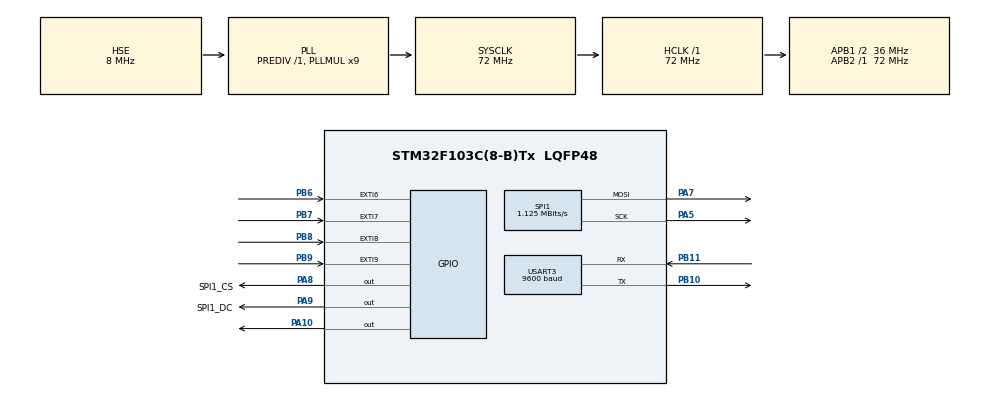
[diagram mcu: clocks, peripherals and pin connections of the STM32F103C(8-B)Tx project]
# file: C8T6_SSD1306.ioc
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Mcu.Family=STM32F1
Mcu.Name=STM32F103C(8-B)Tx
Mcu.Package=LQFP48
NVIC.EXTI9_5_IRQn=true\:0\:0\:false\:false\:true\:true
NVIC.PriorityGroup=NVIC_PRIORITYGROUP_4
NVIC.TIM2_IRQn=true\:0\:0\:false\:false\:true\:true
NVIC.USART3_IRQn=true\:0\:0\:false\:false\:true\:true
PA10.Signal=GPIO_Output
PA5.Mode=TX_Only_Simplex_Unidirect_Master
PA5.Signal=SPI1_SCK
PA7.Mode=TX_Only_Simplex_Unidirect_Master
PA7.Signal=SPI1_MOSI
PA8.GPIO_Label=SPI1_CS
PA8.GPIO_Speed=GPIO_SPEED_FREQ_LOW
PA8.PinState=GPIO_PIN_RESET
PA8.Signal=GPIO_Output
PA9.GPIO_Label=SPI1_DC
PA9.GPIO_Speed=GPIO_SPEED_FREQ_LOW
PA9.PinState=GPIO_PIN_RESET
PA9.Signal=GPIO_Output
PB10.Mode=Asynchronous
PB10.Signal=USART3_TX
PB11.Mode=Asynchronous
PB11.Signal=USART3_RX
PB6.Signal=GPXTI6
PB7.Signal=GPXTI7
PB8.Signal=GPXTI8
PB9.Signal=GPXTI9
PD0-OSC_IN.Mode=HSE-External-Oscillator
PD0-OSC_IN.Signal=RCC_OSC_IN
PD1-OSC_OUT.Mode=HSE-External-Oscillator
PD1-OSC_OUT.Signal=RCC_OSC_OUT
ProjectManager.HeapSize=0x200
ProjectManager.StackSize=0x400
ProjectManager.TargetToolchain=TrueSTUDIO
RCC.ADCPresc=RCC_ADCPCLK2_DIV6
RCC.AHBFreq_Value=72000000
RCC.APB1CLKDivider=RCC_HCLK_DIV2
RCC.APB1Freq_Value=36000000
RCC.APB1TimFreq_Value=72000000
RCC.APB2Freq_Value=72000000
RCC.APB2TimFreq_Value=72000000
RCC.HCLKFreq_Value=72000000
RCC.PLLMUL=RCC_PLL_MUL9
RCC.PLLSourceVirtual=RCC_PLLSOURCE_HSE
RCC.SYSCLKFreq_VALUE=72000000
RCC.SYSCLKSource=RCC_SYSCLKSOURCE_PLLCLK
RCC.USBFreq_Value=72000000
SPI1.BaudRatePrescaler=SPI_BAUDRATEPRESCALER_64
SPI1.CalculateBaudRate=1.125 MBits/s
SPI1.Direction=SPI_DIRECTION_2LINES
SPI1.Mode=SPI_MODE_MASTER
SPI1.VirtualType=VM_MASTER
TIM2.Period=9999
TIM2.Prescaler=7199
USART3.BaudRate=9600
USART3.VirtualMode=VM_ASYNC
VP_SYS_VS_ND.Mode=No_Debug
VP_TIM2_VS_ClockSourceINT.Mode=Internal
board=C8T6_SSD1306

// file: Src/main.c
/**
  ******************************************************************************
  * File Name          : main.c
  * Description        : Main program body
  ******************************************************************************
  ** This notice applies to any and all portions of this file
  * that are not between comment pairs USER CODE BEGIN and
  * USER CODE END. Other portions of this file, whether
  * inserted by the user or by software development tools
  * are owned by their respective copyright owners.
  *
  * COPYRIGHT(c) 2017 STMicroelectronics
  *
  * Redistribution and use in source and binary forms, with or without modification,
  * are permitted provided that the following conditions are met:
  *   1. Redistributions of source code must retain the above copyright notice,
  *      this list of conditions and the following disclaimer.
  *   2. Redistributions in binary form must reproduce the above copyright notice,
  *      this list of conditions and the following disclaimer in the documentation
  *      and/or other materials provided with the distribution.
  *   3. Neither the name of STMicroelectronics nor the names of its contributors
  *      may be used to endorse or promote products derived from this software
  *      without specific prior written permission.
  *
  * THIS SOFTWARE IS PROVIDED BY THE COPYRIGHT HOLDERS AND CONTRIBUTORS "AS IS"
  * AND ANY EXPRESS OR IMPLIED WARRANTIES, INCLUDING, BUT NOT LIMITED TO, THE
  * IMPLIED WARRANTIES OF MERCHANTABILITY AND FITNESS FOR A PARTICULAR PURPOSE ARE
  * DISCLAIMED. IN NO EVENT SHALL THE COPYRIGHT HOLDER OR CONTRIBUTORS BE LIABLE
  * FOR ANY DIRECT, INDIRECT, INCIDENTAL, SPECIAL, EXEMPLARY, OR CONSEQUENTIAL
  * DAMAGES (INCLUDING, BUT NOT LIMITED TO, PROCUREMENT OF SUBSTITUTE GOODS OR
  * SERVICES; LOSS OF USE, DATA, OR PROFITS; OR BUSINESS INTERRUPTION) HOWEVER
  * CAUSED AND ON ANY THEORY OF LIABILITY, WHETHER IN CONTRACT, STRICT LIABILITY,
  * OR TORT (INCLUDING NEGLIGENCE OR OTHERWISE) ARISING IN ANY WAY OUT OF THE USE
  * OF THIS SOFTWARE, EVEN IF ADVISED OF THE POSSIBILITY OF SUCH DAMAGE.
  *
  ******************************************************************************
  */
#include "main.h"
#include "stm32f1xx_hal.h"

/* USER CODE BEGIN Includes */
#include "userDelay.h"
#include "u8g.h"
#include "u8g_arm.h"
// #include "htu21d_i2c.h"

#include <math.h>
#include <stdlib.h>
#include <string.h>
/* USER CODE END Includes */

SPI_HandleTypeDef hspi1;

TIM_HandleTypeDef htim2;

UART_HandleTypeDef huart3;

/* USER CODE BEGIN PV */
/* Private variables ---------------------------------------------------------*/
uint8_t 	i2cTxData;    // i2c transmit data
uint8_t		i2cRxData[3];    // i2c receive data
uint8_t 	Rx_Data3[2];     // usart2 receive data
char		Rx_Str[50],str3[10]="PN : 0000";
uint8_t		count = 0;
uint8_t     SendFlag = 0,R_tgl=0,Relay=0;

u8g_t 		u8g;

/* USER CODE END PV */

void SystemClock_Config(void);
static void MX_GPIO_Init(void);
static void MX_TIM2_Init(void);
static void MX_SPI1_Init(void);
static void MX_USART3_UART_Init(void);

/* USER CODE BEGIN PFP */
/* Private function prototypes -----------------------------------------------*/

/* USER CODE END PFP */

/* USER CODE BEGIN 0 */
void HAL_TIM_PeriodElapsedCallback(TIM_HandleTypeDef *htim);
void HAL_UART_RxCpltCallback(UART_HandleTypeDef *huart);
void HAL_GPIO_EXTI_Callback(uint16_t GPIO_Pin);

void HAL_UART_RxCpltCallback(UART_HandleTypeDef *huart)
{
	if(huart->Instance==USART3){
		if(Rx_Data3[0]==0x0a)
		{
			SendFlag = 1;
		}
		else
		{
			if(Rx_Data3[0]!=0x0d) Rx_Str[count++] = Rx_Data3[0];
		}
		HAL_UART_Receive_IT(&huart3,(uint8_t *)&Rx_Data3, 1);
		// HAL_GPIO_TogglePin(GPIOC, GPIO_PIN_13);
	}
}

void HAL_TIM_PeriodElapsedCallback(TIM_HandleTypeDef *htim)
{
	if(htim->Instance==TIM2) {       // 1 sec interrupt
		  HAL_GPIO_TogglePin(GPIOC, GPIO_PIN_13);
	}

}

void HAL_GPIO_EXTI_Callback(uint16_t GPIO_Pin)
{
			delay_ms(10);
			if(GPIO_Pin==GPIO_PIN_6) R_tgl = 1;
			sprintf(str3,"PN : %04x",GPIO_Pin);
}

/* USER CODE END 0 */

int main(void)
{

  /* MCU Configuration----------------------------------------------------------*/

  /* Reset of all peripherals, Initializes the Flash interface and the Systick. */
  HAL_Init();

  /* Configure the system clock */
  SystemClock_Config();

  /* Initialize all configured peripherals */
  MX_GPIO_Init();
  MX_TIM2_Init();
  MX_SPI1_Init();
  MX_USART3_UART_Init();

  /* USER CODE BEGIN 2 */
  while(HAL_TIM_Base_Start_IT(&htim2)!=HAL_OK);

  // USART Receive Interrupt1,2
  while(HAL_UART_Receive_IT(&huart3, (uint8_t *)Rx_Data3, 1)!=HAL_OK);

  u8g_InitComFn(&u8g, &u8g_dev_sh1106_128x64_hw_spi, u8g_com_hw_spi_fn);
  HAL_Delay(100);

  u8g_FirstPage(&u8g);
  do
  {
       u8g.font = u8g_font_profont12;
       u8g_DrawStr(&u8g, 2, 25," ");
  } while ( u8g_NextPage(&u8g) );

  /* USER CODE END 2 */

  /* Infinite loop */
  /* USER CODE BEGIN WHILE */
  char lcd_prt[30]="waiting...";
  char lcd_len[10]="data..";
  char ante[10]="ant";
  char temp[20]="TEMP :         C",   // 7
	   humi[20]="HUMI :         %",
	   ch4[20]= "CH4  :         %",
	   relay[20]="LIGHT :   "; // 9
  uint8_t  sz=0;

//  memset(lcd_prt,0x00,30);
//  memset(lcd_len,0x00,10);
//  memset(ante,0x00,10);
  while (1)
  {
  /* USER CODE END WHILE */

  /* USER CODE BEGIN 3 */

	  if(SendFlag && count!=0)
	  {
		  if(count==36 || count==37)
		  {
			  memset(ante,0x00,10);
			  memset(lcd_prt,0x00,30);
			  sz = strlen(Rx_Str);
			  if(sz==36)
			  {
				  strncpy(ante,Rx_Str+12,3);
				  strncpy(lcd_prt,Rx_Str+16,20);
			  }
			  else if(sz==37)
			  {
				  strncpy(ante,Rx_Str+12,4);
				  strncpy(lcd_prt,Rx_Str+17,20);
			  }
			  // sprintf(lcd_len,"%05d",sz);
			  strncpy(temp+7,lcd_prt+0,7);
			  strncpy(humi+8,lcd_prt+7,6);
			  strncpy(ch4+8, lcd_prt+13,6);

			  if(lcd_prt[19]=='0')        strncpy(relay+9,"OFF",3);
			  else if(lcd_prt[19]=='1')   strncpy(relay+9,"ON ",3);

			  memset(Rx_Str,0x00,50);
		  }
		  SendFlag=0;
		  count=0;
	  }

	  if(R_tgl)
		{
			if(Relay) HAL_UART_Transmit(&huart3,(uint8_t *)&"at+data=00019C:0\r\n", 18,1000);
			else      HAL_UART_Transmit(&huart3,(uint8_t *)&"at+data=00019C:1\r\n", 18,1000);
			R_tgl = 0;
			Relay^=1;
		}

      u8g_FirstPage(&u8g);
      do
      {
           u8g.font = u8g_font_profont15;
           u8g_DrawStr(&u8g, 2, 10,"ANT : ");
           u8g_DrawStr(&u8g, 40, 10,ante);

           u8g.font = u8g_font_profont12;
           u8g_DrawStr(&u8g, 70, 10,str3);

           u8g.font = u8g_font_profont15;
           u8g_DrawStr(&u8g, 2, 24,temp);
           u8g_DrawStr(&u8g, 2, 36,humi);
           u8g_DrawStr(&u8g, 2, 48,ch4);
           u8g_DrawStr(&u8g, 2, 60,relay);

      } while ( u8g_NextPage(&u8g) );

  }
  /* USER CODE END 3 */

}

/** System Clock Configuration
*/
void SystemClock_Config(void)
{

  RCC_OscInitTypeDef RCC_OscInitStruct;
  RCC_ClkInitTypeDef RCC_ClkInitStruct;

    /**Initializes the CPU, AHB and APB busses clocks
    */
  RCC_OscInitStruct.OscillatorType = RCC_OSCILLATORTYPE_HSE;
  RCC_OscInitStruct.HSEState = RCC_HSE_ON;
  RCC_OscInitStruct.HSEPredivValue = RCC_HSE_PREDIV_DIV1;
  RCC_OscInitStruct.HSIState = RCC_HSI_ON;
  RCC_OscInitStruct.PLL.PLLState = RCC_PLL_ON;
  RCC_OscInitStruct.PLL.PLLSource = RCC_PLLSOURCE_HSE;
  RCC_OscInitStruct.PLL.PLLMUL = RCC_PLL_MUL9;
  if (HAL_RCC_OscConfig(&RCC_OscInitStruct) != HAL_OK)
  {
    _Error_Handler(__FILE__, __LINE__);
  }

    /**Initializes the CPU, AHB and APB busses clocks
    */
  RCC_ClkInitStruct.ClockType = RCC_CLOCKTYPE_HCLK|RCC_CLOCKTYPE_SYSCLK
                              |RCC_CLOCKTYPE_PCLK1|RCC_CLOCKTYPE_PCLK2;
  RCC_ClkInitStruct.SYSCLKSource = RCC_SYSCLKSOURCE_PLLCLK;
  RCC_ClkInitStruct.AHBCLKDivider = RCC_SYSCLK_DIV1;
  RCC_ClkInitStruct.APB1CLKDivider = RCC_HCLK_DIV2;
  RCC_ClkInitStruct.APB2CLKDivider = RCC_HCLK_DIV1;

  if (HAL_RCC_ClockConfig(&RCC_ClkInitStruct, FLASH_LATENCY_2) != HAL_OK)
  {
    _Error_Handler(__FILE__, __LINE__);
  }

    /**Configure the Systick interrupt time
    */
  HAL_SYSTICK_Config(HAL_RCC_GetHCLKFreq()/1000);

    /**Configure the Systick
    */
  HAL_SYSTICK_CLKSourceConfig(SYSTICK_CLKSOURCE_HCLK);

  /* SysTick_IRQn interrupt configuration */
  HAL_NVIC_SetPriority(SysTick_IRQn, 0, 0);
}

/* SPI1 init function */
static void MX_SPI1_Init(void)
{

  /* SPI1 parameter configuration*/
  hspi1.Instance = SPI1;
  hspi1.Init.Mode = SPI_MODE_MASTER;
  hspi1.Init.Direction = SPI_DIRECTION_2LINES;
  hspi1.Init.DataSize = SPI_DATASIZE_8BIT;
  hspi1.Init.CLKPolarity = SPI_POLARITY_LOW;
  hspi1.Init.CLKPhase = SPI_PHASE_1EDGE;
  hspi1.Init.NSS = SPI_NSS_SOFT;
  hspi1.Init.BaudRatePrescaler = SPI_BAUDRATEPRESCALER_64;
  hspi1.Init.FirstBit = SPI_FIRSTBIT_MSB;
  hspi1.Init.TIMode = SPI_TIMODE_DISABLE;
  hspi1.Init.CRCCalculation = SPI_CRCCALCULATION_DISABLE;
  hspi1.Init.CRCPolynomial = 10;
  if (HAL_SPI_Init(&hspi1) != HAL_OK)
  {
    _Error_Handler(__FILE__, __LINE__);
  }

}

/* TIM2 init function */
static void MX_TIM2_Init(void)
{

  TIM_ClockConfigTypeDef sClockSourceConfig;
  TIM_MasterConfigTypeDef sMasterConfig;

  htim2.Instance = TIM2;
  htim2.Init.Prescaler = 7199;
  htim2.Init.CounterMode = TIM_COUNTERMODE_UP;
  htim2.Init.Period = 9999;
  htim2.Init.ClockDivision = TIM_CLOCKDIVISION_DIV1;
  htim2.Init.AutoReloadPreload = TIM_AUTORELOAD_PRELOAD_DISABLE;
  if (HAL_TIM_Base_Init(&htim2) != HAL_OK)
  {
    _Error_Handler(__FILE__, __LINE__);
  }

  sClockSourceConfig.ClockSource = TIM_CLOCKSOURCE_INTERNAL;
  if (HAL_TIM_ConfigClockSource(&htim2, &sClockSourceConfig) != HAL_OK)
  {
    _Error_Handler(__FILE__, __LINE__);
  }

  sMasterConfig.MasterOutputTrigger = TIM_TRGO_RESET;
  sMasterConfig.MasterSlaveMode = TIM_MASTERSLAVEMODE_DISABLE;
  if (HAL_TIMEx_MasterConfigSynchronization(&htim2, &sMasterConfig) != HAL_OK)
  {
    _Error_Handler(__FILE__, __LINE__);
  }

}

/* USART3 init function */
static void MX_USART3_UART_Init(void)
{

  huart3.Instance = USART3;
  huart3.Init.BaudRate = 9600;
  huart3.Init.WordLength = UART_WORDLENGTH_8B;
  huart3.Init.StopBits = UART_STOPBITS_1;
  huart3.Init.Parity = UART_PARITY_NONE;
  huart3.Init.Mode = UART_MODE_TX_RX;
  huart3.Init.HwFlowCtl = UART_HWCONTROL_NONE;
  huart3.Init.OverSampling = UART_OVERSAMPLING_16;
  if (HAL_UART_Init(&huart3) != HAL_OK)
  {
    _Error_Handler(__FILE__, __LINE__);
  }

}

/** Configure pins as
        * Analog
        * Input
        * Output
        * EVENT_OUT
        * EXTI
*/
static void MX_GPIO_Init(void)
{

  GPIO_InitTypeDef GPIO_InitStruct;

  /* GPIO Ports Clock Enable */
  __HAL_RCC_GPIOD_CLK_ENABLE();
  __HAL_RCC_GPIOA_CLK_ENABLE();
  __HAL_RCC_GPIOB_CLK_ENABLE();
  __HAL_RCC_GPIOC_CLK_ENABLE();

  /*Configure GPIO pin Output Level */
  HAL_GPIO_WritePin(GPIOA, SPI1_CS_Pin|SPI1_DC_Pin|GPIO_PIN_10, GPIO_PIN_RESET);
  HAL_GPIO_WritePin(GPIOC, GPIO_PIN_13, GPIO_PIN_RESET);

  GPIO_InitStruct.Pin = GPIO_PIN_13;
  GPIO_InitStruct.Mode = GPIO_MODE_OUTPUT_PP;
  GPIO_InitStruct.Speed = GPIO_SPEED_FREQ_LOW;
  HAL_GPIO_Init(GPIOC, &GPIO_InitStruct);

  /*Configure GPIO pins : SPI1_CS_Pin SPI1_DC_Pin PA10 */
  GPIO_InitStruct.Pin = SPI1_CS_Pin|SPI1_DC_Pin|GPIO_PIN_10;
  GPIO_InitStruct.Mode = GPIO_MODE_OUTPUT_PP;
  GPIO_InitStruct.Speed = GPIO_SPEED_FREQ_LOW;
  HAL_GPIO_Init(GPIOA, &GPIO_InitStruct);

  /*Configure GPIO pins : PB6 PB7 PB8 PB9 */
  GPIO_InitStruct.Pin = GPIO_PIN_6|GPIO_PIN_7|GPIO_PIN_8|GPIO_PIN_9;
  GPIO_InitStruct.Mode = GPIO_MODE_IT_RISING;
  GPIO_InitStruct.Pull = GPIO_NOPULL;
  HAL_GPIO_Init(GPIOB, &GPIO_InitStruct);

  /* EXTI interrupt init*/
  HAL_NVIC_SetPriority(EXTI9_5_IRQn, 0, 0);
  HAL_NVIC_EnableIRQ(EXTI9_5_IRQn);

}

void _Error_Handler(char * file, int line)
{
  while(1)
  {
  }
}

/************************ (C) COPYRIGHT STMicroelectronics *****END OF FILE****/
